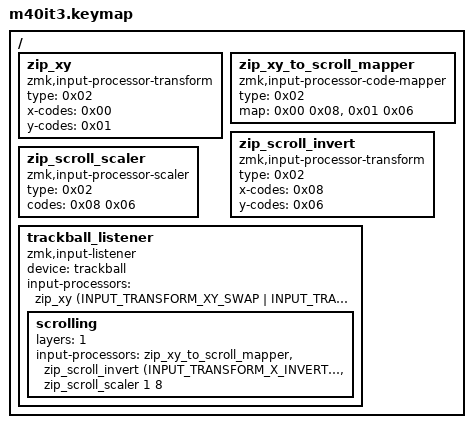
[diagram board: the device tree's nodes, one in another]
#include <behaviors.dtsi>
#include <dt-bindings/zmk/keys.h>
#include <dt-bindings/zmk/input_transform.h>
#include <dt-bindings/zmk/pointing.h>

/ {
    /* 1. 通常移動用の設定（変更なし） */
    zip_xy: zip_xy {
        compatible = "zmk,input-processor-transform";
        #input-processor-cells = <1>;
        type = <0x02>;
        x-codes = <0x00>;
        y-codes = <0x01>;
    };

    /* 2. 移動をスクロール信号に変換（変更なし） */
    zip_xy_to_scroll_mapper: zip_xy_to_scroll_mapper {
        compatible = "zmk,input-processor-code-mapper";
        #input-processor-cells = <0>;
        type = <0x02>;
        map = <0x00 0x08>, <0x01 0x06>;
    };

    /* 3. スクロールの向きを逆転させる設定（変更なし） */
    zip_scroll_invert: zip_scroll_invert {
        compatible = "zmk,input-processor-transform";
        #input-processor-cells = <1>;
        type = <0x02>;
        x-codes = <0x08>; 
        y-codes = <0x06>;
    };

    /* 4. 【ここを調整】スクロールの感度を大幅に下げてブレをカット */
    /* 分母を「12」に設定。これにより微小な動きが切り捨てられます */
    zip_scroll_scaler: zip_scroll_scaler {
        compatible = "zmk,input-processor-scaler";
        #input-processor-cells = <2>;
        type = <0x02>;
        codes = <0x08 0x06>;
    };

    trackball_listener: trackball_listener {
        compatible = "zmk,input-listener";
        device = <&trackball>;
        
        /* 通常時：カーソル移動 */
        input-processors = <&zip_xy (INPUT_TRANSFORM_XY_SWAP | INPUT_TRANSFORM_X_INVERT)>;

        /* Layer 1 (mo 1) 押下時：ブレ抑制スクロール */
        scrolling {
            layers = <1>;
            input-processors = 
                <&zip_xy_to_scroll_mapper>, 
                <&zip_scroll_invert (INPUT_TRANSFORM_X_INVERT | INPUT_TRANSFORM_Y_INVERT)>,
                /* 前回の 1 4 から 1 8 に変更。数字を大きくするほど「小さな動き」を無視します */
                <&zip_scroll_scaler 1 8>;
        };
    };
};

#include "../../../config/keymap.keymap"
